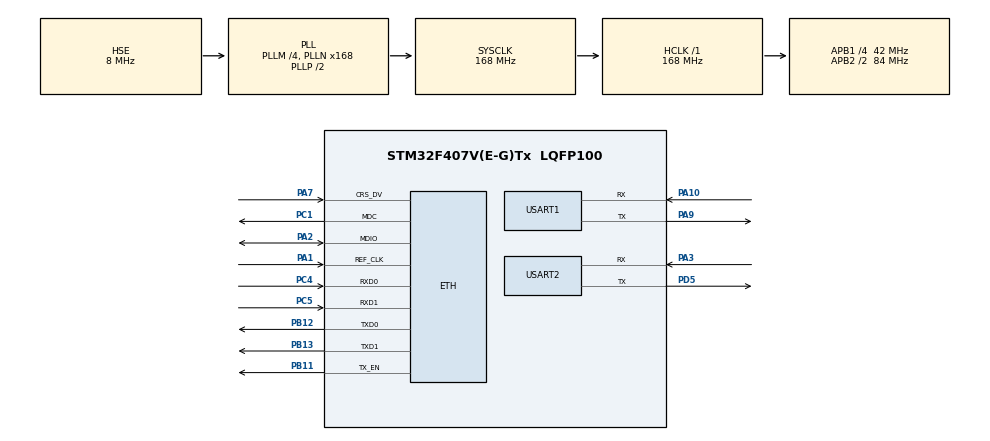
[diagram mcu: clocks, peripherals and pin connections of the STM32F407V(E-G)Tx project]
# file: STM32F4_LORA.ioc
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ETH.MediaInterface=ETH_MEDIA_INTERFACE_RMII
FREERTOS.Tasks01=defaultTask,0,512,StartDefaultTask,Default,NULL,Dynamic,NULL,NULL
FREERTOS.configMINIMAL_STACK_SIZE=512
LWIP.GATEWAY_ADDRESS=010.000.000.001
LWIP.IP_ADDRESS=010.000.000.003
LWIP.LWIP_DBG_MIN_LEVEL=LWIP_DBG_LEVEL_ALL
LWIP.LWIP_DHCP=0
LWIP.LWIP_HTTPD=1
LWIP.MEM_SIZE=2048
LWIP.NETMASK_ADDRESS=255.255.255.000
LWIP.PBUF_POOL_BUFSIZE=2048
LWIP.PPPOS_SUPPORT=1
LWIP.PPP_SUPPORT=1
LWIP.Version=v2.0.3_Cube
Mcu.Family=STM32F4
Mcu.Name=STM32F407V(E-G)Tx
Mcu.Package=LQFP100
NVIC.ETH_IRQn=true\:5\:0\:false\:false\:true\:true\:false
NVIC.PriorityGroup=NVIC_PRIORITYGROUP_4
NVIC.TIM1_UP_TIM10_IRQn=true\:0\:0\:false\:false\:true\:false\:false
NVIC.TimeBase=TIM1_UP_TIM10_IRQn
NVIC.TimeBaseIP=TIM1
NVIC.USART1_IRQn=true\:5\:0\:false\:false\:true\:true\:true
PA1.Mode=RMII
PA1.Signal=ETH_REF_CLK
PA10.Mode=Asynchronous
PA10.Signal=USART1_RX
PA2.Mode=RMII
PA2.Signal=ETH_MDIO
PA3.Mode=Asynchronous
PA3.Signal=USART2_RX
PA7.Mode=RMII
PA7.Signal=ETH_CRS_DV
PA9.Mode=Asynchronous
PA9.Signal=USART1_TX
PB11.Mode=RMII
PB11.Signal=ETH_TX_EN
PB12.Mode=RMII
PB12.Signal=ETH_TXD0
PB13.Mode=RMII
PB13.Signal=ETH_TXD1
PC1.Mode=RMII
PC1.Signal=ETH_MDC
PC4.Mode=RMII
PC4.Signal=ETH_RXD0
PC5.Mode=RMII
PC5.Signal=ETH_RXD1
PD5.Mode=Asynchronous
PD5.Signal=USART2_TX
PH0-OSC_IN.Mode=HSE-External-Clock-Source
PH0-OSC_IN.Signal=RCC_OSC_IN
PH1-OSC_OUT.Mode=HSE-External-Clock-Source
PH1-OSC_OUT.Signal=RCC_OSC_OUT
ProjectManager.HeapSize=0x200
ProjectManager.StackSize=0x800
ProjectManager.TargetToolchain=Makefile
RCC.48MHZClocksFreq_Value=84000000
RCC.AHBFreq_Value=168000000
RCC.APB1CLKDivider=RCC_HCLK_DIV4
RCC.APB1Freq_Value=42000000
RCC.APB1TimFreq_Value=84000000
RCC.APB2CLKDivider=RCC_HCLK_DIV2
RCC.APB2Freq_Value=84000000
RCC.APB2TimFreq_Value=168000000
RCC.CortexFreq_Value=168000000
RCC.HCLKFreq_Value=168000000
RCC.HSE_VALUE=8000000
RCC.HSI_VALUE=16000000
RCC.LSE_VALUE=32768
RCC.PLLM=4
RCC.PLLN=168
RCC.PLLSourceVirtual=RCC_PLLSOURCE_HSE
RCC.SYSCLKFreq_VALUE=168000000
RCC.SYSCLKSource=RCC_SYSCLKSOURCE_PLLCLK
RCC.VCOOutputFreq_Value=336000000
USART1.VirtualMode=VM_ASYNC
USART2.VirtualMode=VM_ASYNC
VP_FREERTOS_VS_ENABLE.Mode=Enabled
VP_LWIP_VS_Enabled.Mode=Enabled
VP_SYS_VS_tim1.Mode=TIM1
board=STM32F4_LORA

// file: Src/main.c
/**
  ******************************************************************************
  * @file           : main.c
  * @brief          : Main program body
  ******************************************************************************
  * This notice applies to any and all portions of this file
  * that are not between comment pairs USER CODE BEGIN and
  * USER CODE END. Other portions of this file, whether
  * inserted by the user or by software development tools
  * are owned by their respective copyright owners.
  *
  * Copyright (c) 2019 STMicroelectronics International N.V.
  * All rights reserved.
  *
  * Redistribution and use in source and binary forms, with or without
  * modification, are permitted, provided that the following conditions are met:
  *
  * 1. Redistribution of source code must retain the above copyright notice,
  *    this list of conditions and the following disclaimer.
  * 2. Redistributions in binary form must reproduce the above copyright notice,
  *    this list of conditions and the following disclaimer in the documentation
  *    and/or other materials provided with the distribution.
  * 3. Neither the name of STMicroelectronics nor the names of other
  *    contributors to this software may be used to endorse or promote products
  *    derived from this software without specific written permission.
  * 4. This software, including modifications and/or derivative works of this
  *    software, must execute solely and exclusively on microcontroller or
  *    microprocessor devices manufactured by or for STMicroelectronics.
  * 5. Redistribution and use of this software other than as permitted under
  *    this license is void and will automatically terminate your rights under
  *    this license.
  *
  * THIS SOFTWARE IS PROVIDED BY STMICROELECTRONICS AND CONTRIBUTORS "AS IS"
  * AND ANY EXPRESS, IMPLIED OR STATUTORY WARRANTIES, INCLUDING, BUT NOT
  * LIMITED TO, THE IMPLIED WARRANTIES OF MERCHANTABILITY, FITNESS FOR A
  * PARTICULAR PURPOSE AND NON-INFRINGEMENT OF THIRD PARTY INTELLECTUAL PROPERTY
  * RIGHTS ARE DISCLAIMED TO THE FULLEST EXTENT PERMITTED BY LAW. IN NO EVENT
  * SHALL STMICROELECTRONICS OR CONTRIBUTORS BE LIABLE FOR ANY DIRECT, INDIRECT,
  * INCIDENTAL, SPECIAL, EXEMPLARY, OR CONSEQUENTIAL DAMAGES (INCLUDING, BUT NOT
  * LIMITED TO, PROCUREMENT OF SUBSTITUTE GOODS OR SERVICES; LOSS OF USE, DATA,
  * OR PROFITS; OR BUSINESS INTERRUPTION) HOWEVER CAUSED AND ON ANY THEORY OF
  * LIABILITY, WHETHER IN CONTRACT, STRICT LIABILITY, OR TORT (INCLUDING
  * NEGLIGENCE OR OTHERWISE) ARISING IN ANY WAY OUT OF THE USE OF THIS SOFTWARE,
  * EVEN IF ADVISED OF THE POSSIBILITY OF SUCH DAMAGE.
  *
  ******************************************************************************
  */
#include "main.h"
#include "stm32f4xx_hal.h"
#include "cmsis_os.h"
#include "lwip.h"

UART_HandleTypeDef huart1;
UART_HandleTypeDef huart2;

osThreadId defaultTaskHandle;

/* USER CODE BEGIN PV */
/* Private variables ---------------------------------------------------------*/

/* USER CODE END PV */

void SystemClock_Config(void);
static void MX_GPIO_Init(void);
static void MX_USART2_UART_Init(void);
static void MX_USART1_UART_Init(void);
void StartDefaultTask(void const * argument);

/* USER CODE BEGIN PFP */
/* Private function prototypes -----------------------------------------------*/

/* USER CODE END PFP */

int main(void)
{

  /* MCU Configuration----------------------------------------------------------*/

  /* Reset of all peripherals, Initializes the Flash interface and the Systick. */
  HAL_Init();

  /* Configure the system clock */
  SystemClock_Config();

  /* Initialize all configured peripherals */
  MX_GPIO_Init();
  MX_USART2_UART_Init();
  MX_USART1_UART_Init();
  /* USER CODE BEGIN 2 */
  //extern void application(void);
  //application();

  //extern void udp_echoserver_init(void);
  //printf("udp_echoserver_init\r\n");
  //udp_echoserver_init();

  /* USER CODE END 2 */

  /* Create the thread(s) */
  /* definition and creation of defaultTask */
  osThreadDef(defaultTask, StartDefaultTask, osPriorityNormal, 0, 512);
  defaultTaskHandle = osThreadCreate(osThread(defaultTask), NULL);

  /* Start scheduler */
  osKernelStart();

  /* We should never get here as control is now taken by the scheduler */

  /* Infinite loop */
  while (1)
  {

  }

}

void SystemClock_Config(void)
{

  RCC_OscInitTypeDef RCC_OscInitStruct;
  RCC_ClkInitTypeDef RCC_ClkInitStruct;

    /**Configure the main internal regulator output voltage
    */
  __HAL_RCC_PWR_CLK_ENABLE();

  __HAL_PWR_VOLTAGESCALING_CONFIG(PWR_REGULATOR_VOLTAGE_SCALE1);

    /**Initializes the CPU, AHB and APB busses clocks
    */
  RCC_OscInitStruct.OscillatorType = RCC_OSCILLATORTYPE_HSE;
  RCC_OscInitStruct.HSEState = RCC_HSE_BYPASS;
  RCC_OscInitStruct.PLL.PLLState = RCC_PLL_ON;
  RCC_OscInitStruct.PLL.PLLSource = RCC_PLLSOURCE_HSE;
  RCC_OscInitStruct.PLL.PLLM = 4;
  RCC_OscInitStruct.PLL.PLLN = 168;
  RCC_OscInitStruct.PLL.PLLP = RCC_PLLP_DIV2;
  RCC_OscInitStruct.PLL.PLLQ = 4;
  if (HAL_RCC_OscConfig(&RCC_OscInitStruct) != HAL_OK)
  {
    _Error_Handler(__FILE__, __LINE__);
  }

    /**Initializes the CPU, AHB and APB busses clocks
    */
  RCC_ClkInitStruct.ClockType = RCC_CLOCKTYPE_HCLK|RCC_CLOCKTYPE_SYSCLK
                              |RCC_CLOCKTYPE_PCLK1|RCC_CLOCKTYPE_PCLK2;
  RCC_ClkInitStruct.SYSCLKSource = RCC_SYSCLKSOURCE_PLLCLK;
  RCC_ClkInitStruct.AHBCLKDivider = RCC_SYSCLK_DIV1;
  RCC_ClkInitStruct.APB1CLKDivider = RCC_HCLK_DIV4;
  RCC_ClkInitStruct.APB2CLKDivider = RCC_HCLK_DIV2;

  if (HAL_RCC_ClockConfig(&RCC_ClkInitStruct, FLASH_LATENCY_5) != HAL_OK)
  {
    _Error_Handler(__FILE__, __LINE__);
  }

    /**Configure the Systick interrupt time
    */
  HAL_SYSTICK_Config(HAL_RCC_GetHCLKFreq()/1000);

    /**Configure the Systick
    */
  HAL_SYSTICK_CLKSourceConfig(SYSTICK_CLKSOURCE_HCLK);

  /* SysTick_IRQn interrupt configuration */
  HAL_NVIC_SetPriority(SysTick_IRQn, 15, 0);
}

/* USART1 init function */
static void MX_USART1_UART_Init(void)
{

  huart1.Instance = USART1;
  huart1.Init.BaudRate = 115200;
  huart1.Init.WordLength = UART_WORDLENGTH_8B;
  huart1.Init.StopBits = UART_STOPBITS_1;
  huart1.Init.Parity = UART_PARITY_NONE;
  huart1.Init.Mode = UART_MODE_TX_RX;
  huart1.Init.HwFlowCtl = UART_HWCONTROL_NONE;
  huart1.Init.OverSampling = UART_OVERSAMPLING_16;
  if (HAL_UART_Init(&huart1) != HAL_OK)
  {
    _Error_Handler(__FILE__, __LINE__);
  }

}

/* USART2 init function */
static void MX_USART2_UART_Init(void)
{

  huart2.Instance = USART2;
  huart2.Init.BaudRate = 115200;
  huart2.Init.WordLength = UART_WORDLENGTH_8B;
  huart2.Init.StopBits = UART_STOPBITS_1;
  huart2.Init.Parity = UART_PARITY_NONE;
  huart2.Init.Mode = UART_MODE_TX_RX;
  huart2.Init.HwFlowCtl = UART_HWCONTROL_NONE;
  huart2.Init.OverSampling = UART_OVERSAMPLING_16;
  if (HAL_UART_Init(&huart2) != HAL_OK)
  {
    _Error_Handler(__FILE__, __LINE__);
  }

}

/** Configure pins as
        * Analog
        * Input
        * Output
        * EVENT_OUT
        * EXTI
*/
static void MX_GPIO_Init(void)
{

  /* GPIO Ports Clock Enable */
  __HAL_RCC_GPIOH_CLK_ENABLE();
  __HAL_RCC_GPIOC_CLK_ENABLE();
  __HAL_RCC_GPIOA_CLK_ENABLE();
  __HAL_RCC_GPIOB_CLK_ENABLE();
  __HAL_RCC_GPIOD_CLK_ENABLE();

}

void StartDefaultTask(void const * argument)
{
  /* init code for LWIP */
  MX_LWIP_Init();

  /* USER CODE BEGIN 5 */
  extern void httpd_init(void);
  httpd_init();

  extern void udp_echoserver_init(void);
  udp_echoserver_init();

  extern struct netif gnetif;

  /* Infinite loop */
  for(;;)
  {
    //osDelay(400);
    //printf("default task\n");
    //slipif_poll(&gnetif);
    //slipif_process_rxqueue(&gnetif);
  }
  /* USER CODE END 5 */
}

void HAL_TIM_PeriodElapsedCallback(TIM_HandleTypeDef *htim)
{
  if (htim->Instance == TIM1) {
    HAL_IncTick();
  }
}

void _Error_Handler(char *file, int line)
{
  while(1)
  {
  }
}

/************************ (C) COPYRIGHT STMicroelectronics *****END OF FILE****/
